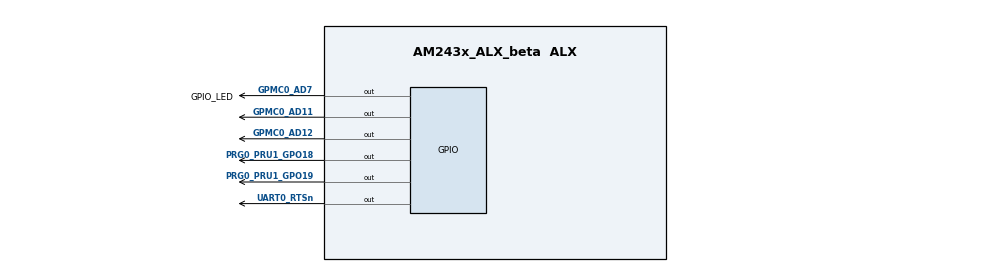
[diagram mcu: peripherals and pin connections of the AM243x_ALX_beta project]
/**
 * @cliArgs --device "AM243x_ALX_beta" --package "ALX" --part "ALX" --context "r5fss0-0" --product "MCU_PLUS_SDK@07.03.01"
 * @versions {"data":"2021040816","timestamp":"2021040816","tool":"1.8.1+1900","templates":null}
 */

/**
 * Import the modules used in this configuration.
 */
const led        = scripting.addModule("/board/led/led", {}, false);
const led1       = led.addInstance();
const led2       = led.addInstance();
const led3       = led.addInstance();
const led4       = led.addInstance();
const led5       = led.addInstance();
const led6       = led.addInstance();
const led7       = led.addInstance();
const gpio       = scripting.addModule("/drivers/gpio/gpio", {}, false);
const gpio1      = gpio.addInstance();
const gpio2      = gpio.addInstance();
const gpio3      = gpio.addInstance();
const gpio4      = gpio.addInstance();
const gpio5      = gpio.addInstance();
const gpio6      = gpio.addInstance();
const i2c        = scripting.addModule("/drivers/i2c/i2c", {}, false);
const i2c1       = i2c.addInstance();
const clock      = scripting.addModule("/kernel/dpl/clock");
const debug_log  = scripting.addModule("/kernel/dpl/debug_log");
const mpu_armv7  = scripting.addModule("/kernel/dpl/mpu_armv7", {}, false);
const mpu_armv71 = mpu_armv7.addInstance();
const mpu_armv72 = mpu_armv7.addInstance();
const mpu_armv73 = mpu_armv7.addInstance();
const mpu_armv74 = mpu_armv7.addInstance();

/**
 * Write custom configuration values to the imported modules.
 */
led1.$name = "CONFIG_LED_GPIO";

led2.$name = "CONFIG_LED_TPIC";
led2.name  = "TPIC2810";

led3.$name = "CONFIG_LED0";

led4.$name = "CONFIG_LED1";

led5.$name = "CONFIG_LED2";

led6.$name = "CONFIG_LED3";

led7.$name = "CONFIG_LED4";

gpio1.$name                = "GPIO_LED";
gpio1.pinDir               = "OUTPUT";
led1.peripheralDriver      = gpio1;
gpio1.GPIO.$assign         = "GPIO0";
gpio1.GPIO.gpioPin.$assign = "GPMC0_AD7";

gpio2.$name                = "CONFIG_GPIO0";
led3.peripheralDriver      = gpio2;
gpio2.GPIO.$assign         = "GPIO0";
gpio2.GPIO.gpioPin.$assign = "GPMC0_AD11";

gpio3.$name                = "CONFIG_GPIO1";
led4.peripheralDriver      = gpio3;
gpio3.GPIO.$assign         = "GPIO0";
gpio3.GPIO.gpioPin.$assign = "GPMC0_AD12";

gpio4.$name                = "CONFIG_GPIO2";
led5.peripheralDriver      = gpio4;
gpio4.GPIO.$assign         = "GPIO1";
gpio4.GPIO.gpioPin.$assign = "PRG0_PRU1_GPO18";

gpio5.$name                = "CONFIG_GPIO3";
led6.peripheralDriver      = gpio5;
gpio5.GPIO.$assign         = "GPIO1";
gpio5.GPIO.gpioPin.$assign = "PRG0_PRU1_GPO19";

gpio6.$name                = "CONFIG_GPIO4";
led7.peripheralDriver      = gpio6;
gpio6.GPIO.$assign         = "GPIO1";
gpio6.GPIO.gpioPin.$assign = "UART0_RTSn";

i2c1.$name            = "CONFIG_I2C0";
led2.peripheralDriver = i2c1;
i2c1.I2C.$assign      = "I2C0";
i2c1.I2C.SCL.$assign  = "I2C0_SCL";
i2c1.I2C.SDA.$assign  = "I2C0_SDA";

debug_log.enableUartLog            = true;
debug_log.uartLog.$name            = "CONFIG_UART_LOG";
debug_log.uartLog.UART.$assign     = "USART0";
debug_log.uartLog.UART.RXD.$assign = "UART0_RXD";
debug_log.uartLog.UART.TXD.$assign = "UART0_TXD";

mpu_armv71.$name             = "CONFIG_MPU_REGION0";
mpu_armv71.size              = 31;
mpu_armv71.attributes        = "Device";
mpu_armv71.accessPermissions = "Supervisor RD+WR, User RD";
mpu_armv71.allowExecute      = false;

mpu_armv72.$name             = "CONFIG_MPU_REGION1";
mpu_armv72.size              = 15;
mpu_armv72.accessPermissions = "Supervisor RD+WR, User RD";

mpu_armv73.$name             = "CONFIG_MPU_REGION2";
mpu_armv73.baseAddr          = 0x41010000;
mpu_armv73.size              = 15;
mpu_armv73.accessPermissions = "Supervisor RD+WR, User RD";

mpu_armv74.$name             = "CONFIG_MPU_REGION3";
mpu_armv74.baseAddr          = 0x70000000;
mpu_armv74.size              = 21;
mpu_armv74.accessPermissions = "Supervisor RD+WR, User RD";
